# SN32F240B register map
Vendor: SONiX Technology Co., Ltd.; Series: SN32F240B; File version: 1.1
ARM 32-bit Cortex-M0 Microcontroller based device, CPU clock up to 48MHz, etc.
CPU: CM0 r0p0, little endian, no MPU, no FPU, 2 interrupt priority bits
Registers are 32-bit, read-write, reset 0x0 unless marked. A register's access mark holds for its fields unless they carry their own. Offsets are from the block's base; lines under a group give offsets from that group; [hi:lo] are bit positions; {n}, {i} and the like mark numbered series; 'fields as' and 'values as' point back to an identical list; <NAME> marks a mode.

## Memory map
0x1FFF2228 SN_UC size 0x2000 — UC Registers
0x40000000 SN_CT16B0 size 0x2000 — 16-bit Timer 0 with Capture function
0x40002000 SN_CT16B1 size 0x2000 — 16-bit Timer 0 with Capture function
0x40010000 SN_WDT size 0x2000 — Watchdog Timer
0x40012000 SN_UART2 size 0x2000 — UART2
0x40014000 SN_UART1 size 0x2000 — UART1
0x40016000 SN_UART0 size 0x2000 — UART0
0x40018000 SN_I2C0 size 0x2000 — I2C0
0x4001C000 SN_SPI0 size 0x2000 — SPI0
0x40026000 SN_ADC size 0x2000 — ADC
0x40032000 SN_PMU size 0x2000 — Power Management Unit
0x40042000 SN_PFPA size 0x2000 — Peripheral Function Pin Assignment
0x40044000 SN_GPIO0 size 0x2000 — General Purpose I/O
0x40046000 SN_GPIO1 size 0x2000
0x40048000 SN_GPIO2 size 0x2000
0x4004A000 SN_GPIO3 size 0x2000 — General Purpose I/O
0x4005C000 SN_USB size 0x2000 — Universal Serial Bus Full Speed Device Interface (USB)
0x4005E000 SN_SYS1 size 0x2000 — System Control Registers
0x40060000 SN_SYS0 size 0x2000 — System Control Registers
0x40062000 SN_FLASH size 0x2000 — FLASH Memory Control Registers

## Interrupts
0 NDT (SN_PMU)
1 USB (SN_USB)
6 SPI0 (SN_SPI0)
10 I2C0 (SN_I2C0)
12 UART0 (SN_UART0)
13 UART1 (SN_UART1)
14 UART2 (SN_UART2)
15 CT16B0 (SN_CT16B0)
16 CT16B1 (SN_CT16B1)
24 ADC (SN_ADC)
25 WDT (SN_WDT)
26 LVD (SN_SYS0)
28 P3 (SN_GPIO3)
29 P2 (SN_GPIO2)
30 P1 (SN_GPIO1)
31 P0 (SN_GPIO0)

## SN_SYS0 — System Control Registers
Base 0x40060000
0x00 ANBCTRL reset 0x1 — Offset:0x00 Analog Block Control Register
  [0] IHRCEN — IHRC enable
    0=Disable IHRC; 1=Enable IHRC
0x08 CSST ro reset 0x1 — Offset:0x08 Clock Source Status Register
  [0] IHRCRDY — IHRC ready flag
    0=IHRC is Not Ready; 1=IHRC is Ready
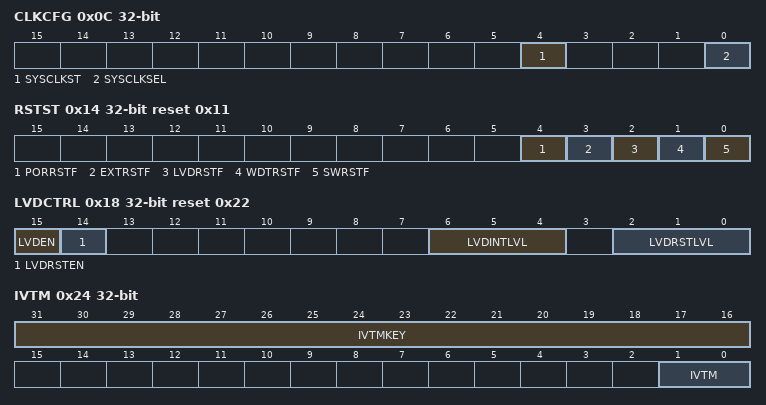
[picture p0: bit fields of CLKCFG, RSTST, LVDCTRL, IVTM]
0x0C CLKCFG — Offset:0x0C System Clock Configuration Register
  [4] SYSCLKST ro — System clock switch status
    0=IHRC (IHRC is used as system clock); 1=ILRC (ILRC is used as system clock)
  [0] SYSCLKSEL — System clock source selection
    0=IHRC (IHRC is system clock); 1=ILRC (ILRC is system clock)
0x10 AHBCP reset 0x2 — Offset:0x10 AHB Clock Prescale Register
  [2:0] AHBPRE — AHB clock source prescaler
    0=FAHB=FSYSCLK/1; 1=FAHB=FSYSCLK/2; 2=FAHB=FSYSCLK/4; 3=FAHB=FSYSCLK/8; 4=FAHB=FSYSCLK/16; 5=FAHB=FSYSCLK/32; 6=FAHB=FSYSCLK/64; 7=FAHB=FSYSCLK/128
0x14 RSTST reset 0x11 — Offset:0x14 System Reset Status Register
  [4] PORRSTF — POR reset flag
    0=No POR occurred; 1=POR occurred
  [3] EXTRSTF — External reset flag
    0=No Extenral reset occurred; 1=External reset occurred
  [2] LVDRSTF — LVD reset flag
    0=No LVD reset occurred; 1=LVD reset occurred
  [1] WDTRSTF — WDT reset flag
    0=No WDT reset occurred; 1=WDT reset occurred
  [0] SWRSTF — Software reset flag
    0=No SW reset occurred; 1=SW reset occurred
0x18 LVDCTRL reset 0x22 (reset mask 0x8077) — Offset:0x18 LVD Control Register
  [15] LVDEN — LVD enable
    0=Diable (Disable LVD); 1=Enable LVD
  [14] LVDRSTEN — LVD Reset enable
    0=Diable (Disable LVD reset); 1=Enable LVD reset
  [6:4] LVDINTLVL — LVD interrupt level
    2=2.40V (LVD interrupt threshold is 2.40V); 3=2.70V (LVD interrupt threshold is 2.70V); 4=3.00V (LVD interrupt threshold is 3.00V); 5=3.60V (LVD interrupt threshold is 3.60V)
  [2:0] LVDRSTLVL — LVD reset level
    2=2.40V (LVD reset threshold is 2.40V); 3=2.70V (LVD reset threshold is 2.70V); 4=3.00V (LVD reset threshold is 3.00V); 5=3.60V (LVD reset threshold is 3.60V)
0x1C EXRSTCTRL reset 0x1 — Offset:0x1C External Reset Pin Control Register
  [0] RESETDIS — External reset pin disable
    0=Enable (P3.7 acts as nRESET pin); 1=Disable (P3.7 acts as GPIO pin)
0x20 SWDCTRL — Offset:0x20 SWD Pin Control Register
  [0] SWDDIS — SWD pin disable
    0=Enable SWD pins; 1=Disable SWD pins
0x24 IVTM (reset mask 0x1) — Offset:0x24 Interrupt Vector Table Mapping register
  [31:16] IVTMKEY wo — IVTM register key
  [1:0] IVTM — Interrupt table mapping selection
    0=Map to Boot ROM; 1=Map to User ROM; 2=Map to SRAM
0x28 NDTCTRL — Offset:0x28 Noise Detect Control Register
  [1] NDT5V_IE — NDT for VDD 5V interrupt enable bit
    0=Disable; 1=Enable
0x2C NDTSTS — Offset:0x2C Noise Detect Status Register
  [1] NDT5V_DET — Power noise status of NDT5V
    0=No (No power noise is detected); 1=Detected (Power noise is detected by NDT5V IP)
0x30 ANTIEFT — Offset:0x30 Anti-EFT Ability Control Register
  [2:0] AEFT — Anti-EFT ability
    0=No; 2=Low; 3=Medium; 4=Strong

## Licence text in the file
ARM Limited (ARM) is supplying this software for use with Cortex-M processor based microcontroller, but can be equally used for other suitable processor architectures. This file can be freely distributed. Modifications to this file shall be clearly marked. . THIS SOFTWARE IS PROVIDED "AS IS". NO WARRANTIES, WHETHER EXPRESS, IMPLIED. OR STATUTORY, INCLUDING, BUT NOT LIMITED TO, IMPLIED WARRANTIES OF. MERCHANTABILITY AND FITNESS FOR A PARTICULAR PURPOSE APPLY TO THIS SOFTWARE. ARM SHALL NOT, IN ANY CIRCUMSTANCES, BE LIABLE FOR SPECIAL, INCIDENTAL, OR. CONSEQUENTIAL DAMAGES, FOR ANY REASON WHATSOEVER.

## Notices in the file
Copyright (C) 2019 ARM Limited. All rights reserved.
